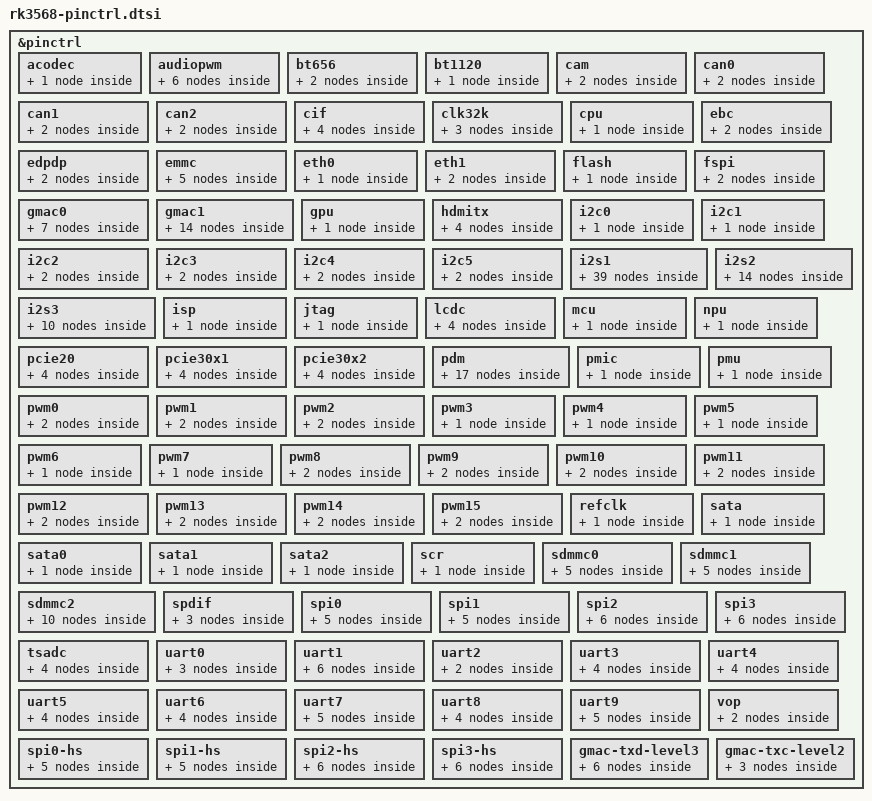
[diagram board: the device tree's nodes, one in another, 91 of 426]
#include <dt-bindings/pinctrl/rockchip.h>
#include "rockchip-pinconf.dtsi"
&pinctrl {
	acodec {
		/omit-if-no-ref/
		acodec_pins: acodec-pins {
			rockchip,pins =
				<1 RK_PB1 5 &pcfg_pull_none>,
				<1 RK_PA1 5 &pcfg_pull_none>,
				<1 RK_PA0 5 &pcfg_pull_none>,
				<1 RK_PA7 5 &pcfg_pull_none>,
				<1 RK_PB0 5 &pcfg_pull_none>,
				<1 RK_PA3 5 &pcfg_pull_none>,
				<1 RK_PA5 5 &pcfg_pull_none>;
		};
	};
	audiopwm {
		/omit-if-no-ref/
		audiopwm_lout: audiopwm-lout {
			rockchip,pins =
				<1 RK_PA0 4 &pcfg_pull_none>;
		};
		/omit-if-no-ref/
		audiopwm_loutn: audiopwm-loutn {
			rockchip,pins =
				<1 RK_PA1 6 &pcfg_pull_none>;
		};
		/omit-if-no-ref/
		audiopwm_loutp: audiopwm-loutp {
			rockchip,pins =
				<1 RK_PA0 6 &pcfg_pull_none>;
		};
		/omit-if-no-ref/
		audiopwm_rout: audiopwm-rout {
			rockchip,pins =
				<1 RK_PA1 4 &pcfg_pull_none>;
		};
		/omit-if-no-ref/
		audiopwm_routn: audiopwm-routn {
			rockchip,pins =
				<1 RK_PA7 4 &pcfg_pull_none>;
		};
		/omit-if-no-ref/
		audiopwm_routp: audiopwm-routp {
			rockchip,pins =
				<1 RK_PA6 4 &pcfg_pull_none>;
		};
	};
	bt656 {
		/omit-if-no-ref/
		bt656m0_pins: bt656m0-pins {
			rockchip,pins =
				<3 RK_PA0 2 &pcfg_pull_none>,
				<2 RK_PD0 2 &pcfg_pull_none>,
				<2 RK_PD1 2 &pcfg_pull_none>,
				<2 RK_PD2 2 &pcfg_pull_none>,
				<2 RK_PD3 2 &pcfg_pull_none>,
				<2 RK_PD4 2 &pcfg_pull_none>,
				<2 RK_PD5 2 &pcfg_pull_none>,
				<2 RK_PD6 2 &pcfg_pull_none>,
				<2 RK_PD7 2 &pcfg_pull_none>;
		};
		/omit-if-no-ref/
		bt656m1_pins: bt656m1-pins {
			rockchip,pins =
				<4 RK_PB4 5 &pcfg_pull_none>,
				<3 RK_PC6 5 &pcfg_pull_none>,
				<3 RK_PC7 5 &pcfg_pull_none>,
				<3 RK_PD0 5 &pcfg_pull_none>,
				<3 RK_PD1 5 &pcfg_pull_none>,
				<3 RK_PD2 5 &pcfg_pull_none>,
				<3 RK_PD3 5 &pcfg_pull_none>,
				<3 RK_PD4 5 &pcfg_pull_none>,
				<3 RK_PD5 5 &pcfg_pull_none>;
		};
	};
	bt1120 {
		/omit-if-no-ref/
		bt1120_pins: bt1120-pins {
			rockchip,pins =
				<3 RK_PA6 2 &pcfg_pull_none>,
				<3 RK_PA1 2 &pcfg_pull_none>,
				<3 RK_PA2 2 &pcfg_pull_none>,
				<3 RK_PA3 2 &pcfg_pull_none>,
				<3 RK_PA4 2 &pcfg_pull_none>,
				<3 RK_PA5 2 &pcfg_pull_none>,
				<3 RK_PA7 2 &pcfg_pull_none>,
				<3 RK_PB0 2 &pcfg_pull_none>,
				<3 RK_PB1 2 &pcfg_pull_none>,
				<3 RK_PB2 2 &pcfg_pull_none>,
				<3 RK_PB3 2 &pcfg_pull_none>,
				<3 RK_PB4 2 &pcfg_pull_none>,
				<3 RK_PB5 2 &pcfg_pull_none>,
				<3 RK_PB6 2 &pcfg_pull_none>,
				<3 RK_PC1 2 &pcfg_pull_none>,
				<3 RK_PC2 2 &pcfg_pull_none>,
				<3 RK_PC3 2 &pcfg_pull_none>;
		};
	};
	cam {
		/omit-if-no-ref/
		cam_clkout0: cam-clkout0 {
			rockchip,pins =
				<4 RK_PA7 1 &pcfg_pull_none>;
		};
		/omit-if-no-ref/
		cam_clkout1: cam-clkout1 {
			rockchip,pins =
				<4 RK_PB0 1 &pcfg_pull_none>;
		};
	};
	can0 {
		/omit-if-no-ref/
		can0m0_pins: can0m0-pins {
			rockchip,pins =
				<0 RK_PB4 2 &pcfg_pull_none>,
				<0 RK_PB3 2 &pcfg_pull_none>;
		};
		/omit-if-no-ref/
		can0m1_pins: can0m1-pins {
			rockchip,pins =
				<2 RK_PA2 4 &pcfg_pull_none>,
				<2 RK_PA1 4 &pcfg_pull_none>;
		};
	};
	can1 {
		/omit-if-no-ref/
		can1m0_pins: can1m0-pins {
			rockchip,pins =
				<1 RK_PA0 3 &pcfg_pull_none>,
				<1 RK_PA1 3 &pcfg_pull_none>;
		};
		/omit-if-no-ref/
		can1m1_pins: can1m1-pins {
			rockchip,pins =
				<4 RK_PC2 3 &pcfg_pull_none>,
				<4 RK_PC3 3 &pcfg_pull_none>;
		};
	};
	can2 {
		/omit-if-no-ref/
		can2m0_pins: can2m0-pins {
			rockchip,pins =
				<4 RK_PB4 3 &pcfg_pull_none>,
				<4 RK_PB5 3 &pcfg_pull_none>;
		};
		/omit-if-no-ref/
		can2m1_pins: can2m1-pins {
			rockchip,pins =
				<2 RK_PB1 4 &pcfg_pull_none>,
				<2 RK_PB2 4 &pcfg_pull_none>;
		};
	};
	cif {
		/omit-if-no-ref/
		cif_clk: cif-clk {
			rockchip,pins =
				<4 RK_PC0 1 &pcfg_pull_none>;
		};
		/omit-if-no-ref/
		cif_dvp_clk: cif-dvp-clk {
			rockchip,pins =
				<4 RK_PC1 1 &pcfg_pull_none>,
				<4 RK_PB6 1 &pcfg_pull_none>,
				<4 RK_PB7 1 &pcfg_pull_none>;
		};
		/omit-if-no-ref/
		cif_dvp_bus16: cif-dvp-bus16 {
			rockchip,pins =
				<3 RK_PD6 1 &pcfg_pull_none>,
				<3 RK_PD7 1 &pcfg_pull_none>,
				<4 RK_PA0 1 &pcfg_pull_none>,
				<4 RK_PA1 1 &pcfg_pull_none>,
				<4 RK_PA2 1 &pcfg_pull_none>,
				<4 RK_PA3 1 &pcfg_pull_none>,
				<4 RK_PA4 1 &pcfg_pull_none>,
				<4 RK_PA5 1 &pcfg_pull_none>;
		};
		/omit-if-no-ref/
		cif_dvp_bus8: cif-dvp-bus8 {
			rockchip,pins =
				<3 RK_PC6 1 &pcfg_pull_none>,
				<3 RK_PC7 1 &pcfg_pull_none>,
				<3 RK_PD0 1 &pcfg_pull_none>,
				<3 RK_PD1 1 &pcfg_pull_none>,
				<3 RK_PD2 1 &pcfg_pull_none>,
				<3 RK_PD3 1 &pcfg_pull_none>,
				<3 RK_PD4 1 &pcfg_pull_none>,
				<3 RK_PD5 1 &pcfg_pull_none>;
		};
	};
	clk32k {
		/omit-if-no-ref/
		clk32k_in: clk32k-in {
			rockchip,pins =
				<0 RK_PB0 1 &pcfg_pull_none>;
		};
		/omit-if-no-ref/
		clk32k_out0: clk32k-out0 {
			rockchip,pins =
				<0 RK_PB0 2 &pcfg_pull_none>;
		};
		/omit-if-no-ref/
		clk32k_out1: clk32k-out1 {
			rockchip,pins =
				<2 RK_PC6 1 &pcfg_pull_none>;
		};
	};
	cpu {
		/omit-if-no-ref/
		cpu_pins: cpu-pins {
			rockchip,pins =
				<0 RK_PB7 2 &pcfg_pull_none>;
		};
	};
	ebc {
		/omit-if-no-ref/
		ebc_extern: ebc-extern {
			rockchip,pins =
				<4 RK_PA7 2 &pcfg_pull_none>,
				<4 RK_PB0 2 &pcfg_pull_none>,
				<4 RK_PB1 2 &pcfg_pull_none>,
				<4 RK_PB5 2 &pcfg_pull_none>,
				<4 RK_PB2 2 &pcfg_pull_none>;
		};
		/omit-if-no-ref/
		ebc_pins: ebc-pins {
			rockchip,pins =
				<4 RK_PC0 2 &pcfg_pull_none>,
				<4 RK_PB3 2 &pcfg_pull_none>,
				<4 RK_PB4 2 &pcfg_pull_none>,
				<4 RK_PA6 2 &pcfg_pull_none>,
				<4 RK_PC1 2 &pcfg_pull_none>,
				<3 RK_PC6 2 &pcfg_pull_none>,
				<3 RK_PC7 2 &pcfg_pull_none>,
				<3 RK_PD0 2 &pcfg_pull_none>,
				<3 RK_PD1 2 &pcfg_pull_none>,
				<3 RK_PD2 2 &pcfg_pull_none>,
				<3 RK_PD3 2 &pcfg_pull_none>,
				<3 RK_PD4 2 &pcfg_pull_none>,
				<3 RK_PD5 2 &pcfg_pull_none>,
				<3 RK_PD6 2 &pcfg_pull_none>,
				<3 RK_PD7 2 &pcfg_pull_none>,
				<4 RK_PA0 2 &pcfg_pull_none>,
				<4 RK_PA1 2 &pcfg_pull_none>,
				<4 RK_PA2 2 &pcfg_pull_none>,
				<4 RK_PA3 2 &pcfg_pull_none>,
				<4 RK_PA4 2 &pcfg_pull_none>,
				<4 RK_PA5 2 &pcfg_pull_none>,
				<4 RK_PB6 2 &pcfg_pull_none>,
				<4 RK_PB7 2 &pcfg_pull_none>;
		};
	};
	edpdp {
		/omit-if-no-ref/
		edpdpm0_pins: edpdpm0-pins {
			rockchip,pins =
				<4 RK_PC4 1 &pcfg_pull_none>;
		};
		/omit-if-no-ref/
		edpdpm1_pins: edpdpm1-pins {
			rockchip,pins =
				<0 RK_PC2 2 &pcfg_pull_none>;
		};
	};
	emmc {
		/omit-if-no-ref/
		emmc_rstnout: emmc-rstnout {
			rockchip,pins =
				<1 RK_PC7 1 &pcfg_pull_none>;
		};
		/omit-if-no-ref/
		emmc_bus8: emmc-bus8 {
			rockchip,pins =
				<1 RK_PB4 1 &pcfg_pull_up_drv_level_2>,
				<1 RK_PB5 1 &pcfg_pull_up_drv_level_2>,
				<1 RK_PB6 1 &pcfg_pull_up_drv_level_2>,
				<1 RK_PB7 1 &pcfg_pull_up_drv_level_2>,
				<1 RK_PC0 1 &pcfg_pull_up_drv_level_2>,
				<1 RK_PC1 1 &pcfg_pull_up_drv_level_2>,
				<1 RK_PC2 1 &pcfg_pull_up_drv_level_2>,
				<1 RK_PC3 1 &pcfg_pull_up_drv_level_2>;
		};
		/omit-if-no-ref/
		emmc_clk: emmc-clk {
			rockchip,pins =
				<1 RK_PC5 1 &pcfg_pull_up_drv_level_2>;
		};
		/omit-if-no-ref/
		emmc_cmd: emmc-cmd {
			rockchip,pins =
				<1 RK_PC4 1 &pcfg_pull_up_drv_level_2>;
		};
		/omit-if-no-ref/
		emmc_datastrobe: emmc-datastrobe {
			rockchip,pins =
				<1 RK_PC6 1 &pcfg_pull_none>;
		};
	};
	eth0 {
		/omit-if-no-ref/
		eth0_pins: eth0-pins {
			rockchip,pins =
				<2 RK_PC1 2 &pcfg_pull_none>;
		};
	};
	eth1 {
		/omit-if-no-ref/
		eth1m0_pins: eth1m0-pins {
			rockchip,pins =
				<3 RK_PB0 3 &pcfg_pull_none>;
		};
		/omit-if-no-ref/
		eth1m1_pins: eth1m1-pins {
			rockchip,pins =
				<4 RK_PB3 3 &pcfg_pull_none>;
		};
	};
	flash {
		/omit-if-no-ref/
		flash_pins: flash-pins {
			rockchip,pins =
				<1 RK_PD0 2 &pcfg_pull_none>,
				<1 RK_PC6 3 &pcfg_pull_none>,
				<1 RK_PD3 2 &pcfg_pull_none>,
				<1 RK_PD4 2 &pcfg_pull_none>,
				<1 RK_PB4 2 &pcfg_pull_none>,
				<1 RK_PB5 2 &pcfg_pull_none>,
				<1 RK_PB6 2 &pcfg_pull_none>,
				<1 RK_PB7 2 &pcfg_pull_none>,
				<1 RK_PC0 2 &pcfg_pull_none>,
				<1 RK_PC1 2 &pcfg_pull_none>,
				<1 RK_PC2 2 &pcfg_pull_none>,
				<1 RK_PC3 2 &pcfg_pull_none>,
				<1 RK_PC5 2 &pcfg_pull_none>,
				<1 RK_PD2 2 &pcfg_pull_none>,
				<1 RK_PD1 2 &pcfg_pull_none>,
				<0 RK_PA7 1 &pcfg_pull_none>,
				<1 RK_PC7 3 &pcfg_pull_none>,
				<1 RK_PC4 2 &pcfg_pull_none>;
		};
	};
	fspi {
		/omit-if-no-ref/
		fspi_pins: fspi-pins {
			rockchip,pins =
				<1 RK_PD0 1 &pcfg_pull_none>,
				<1 RK_PD3 1 &pcfg_pull_none>,
				<1 RK_PD1 1 &pcfg_pull_none>,
				<1 RK_PD2 1 &pcfg_pull_none>,
				<1 RK_PC7 2 &pcfg_pull_none>,
				<1 RK_PD4 1 &pcfg_pull_none>;
		};
		/omit-if-no-ref/
		fspi_cs1: fspi-cs1 {
			rockchip,pins =
				<1 RK_PC6 2 &pcfg_pull_up>;
		};
	};
	gmac0 {
		/omit-if-no-ref/
		gmac0_miim: gmac0-miim {
			rockchip,pins =
				<2 RK_PC3 2 &pcfg_pull_none>,
				<2 RK_PC4 2 &pcfg_pull_none>;
		};
		/omit-if-no-ref/
		gmac0_clkinout: gmac0-clkinout {
			rockchip,pins =
				<2 RK_PC2 2 &pcfg_pull_none>;
		};
		/omit-if-no-ref/
		gmac0_rx_er: gmac0-rx-er {
			rockchip,pins =
				<2 RK_PC5 2 &pcfg_pull_none>;
		};
		/omit-if-no-ref/
		gmac0_rx_bus2: gmac0-rx-bus2 {
			rockchip,pins =
				<2 RK_PB6 1 &pcfg_pull_none>,
				<2 RK_PB7 2 &pcfg_pull_none>,
				<2 RK_PC0 2 &pcfg_pull_none>;
		};
		/omit-if-no-ref/
		gmac0_tx_bus2: gmac0-tx-bus2 {
			rockchip,pins =
				<2 RK_PB3 1 &pcfg_pull_none_drv_level_2>,
				<2 RK_PB4 1 &pcfg_pull_none_drv_level_2>,
				<2 RK_PB5 1 &pcfg_pull_none>;
		};
		/omit-if-no-ref/
		gmac0_rgmii_clk: gmac0-rgmii-clk {
			rockchip,pins =
				<2 RK_PA5 2 &pcfg_pull_none>,
				<2 RK_PB0 2 &pcfg_pull_none_drv_level_1>;
		};
		/omit-if-no-ref/
		gmac0_rgmii_bus: gmac0-rgmii-bus {
			rockchip,pins =
				<2 RK_PA3 2 &pcfg_pull_none>,
				<2 RK_PA4 2 &pcfg_pull_none>,
				<2 RK_PA6 2 &pcfg_pull_none_drv_level_2>,
				<2 RK_PA7 2 &pcfg_pull_none_drv_level_2>;
		};
	};
	gmac1 {
		/omit-if-no-ref/
		gmac1m0_miim: gmac1m0-miim {
			rockchip,pins =
				<3 RK_PC4 3 &pcfg_pull_none>,
				<3 RK_PC5 3 &pcfg_pull_none>;
		};
		/omit-if-no-ref/
		gmac1m0_clkinout: gmac1m0-clkinout {
			rockchip,pins =
				<3 RK_PC0 3 &pcfg_pull_none>;
		};
		/omit-if-no-ref/
		gmac1m0_rx_er: gmac1m0-rx-er {
			rockchip,pins =
				<3 RK_PB4 3 &pcfg_pull_none>;
		};
		/omit-if-no-ref/
		gmac1m0_rx_bus2: gmac1m0-rx-bus2 {
			rockchip,pins =
				<3 RK_PB1 3 &pcfg_pull_none>,
				<3 RK_PB2 3 &pcfg_pull_none>,
				<3 RK_PB3 3 &pcfg_pull_none>;
		};
		/omit-if-no-ref/
		gmac1m0_tx_bus2: gmac1m0-tx-bus2 {
			rockchip,pins =
				<3 RK_PB5 3 &pcfg_pull_none_drv_level_2>,
				<3 RK_PB6 3 &pcfg_pull_none_drv_level_2>,
				<3 RK_PB7 3 &pcfg_pull_none>;
		};
		/omit-if-no-ref/
		gmac1m0_rgmii_clk: gmac1m0-rgmii-clk {
			rockchip,pins =
				<3 RK_PA7 3 &pcfg_pull_none>,
				<3 RK_PA6 3 &pcfg_pull_none_drv_level_1>;
		};
		/omit-if-no-ref/
		gmac1m0_rgmii_bus: gmac1m0-rgmii-bus {
			rockchip,pins =
				<3 RK_PA4 3 &pcfg_pull_none>,
				<3 RK_PA5 3 &pcfg_pull_none>,
				<3 RK_PA2 3 &pcfg_pull_none_drv_level_2>,
				<3 RK_PA3 3 &pcfg_pull_none_drv_level_2>;
		};
		/omit-if-no-ref/
		gmac1m1_miim: gmac1m1-miim {
			rockchip,pins =
				<4 RK_PB6 3 &pcfg_pull_none>,
				<4 RK_PB7 3 &pcfg_pull_none>;
		};
		/omit-if-no-ref/
		gmac1m1_clkinout: gmac1m1-clkinout {
			rockchip,pins =
				<4 RK_PC1 3 &pcfg_pull_none>;
		};
		/omit-if-no-ref/
		gmac1m1_rx_er: gmac1m1-rx-er {
			rockchip,pins =
				<4 RK_PB2 3 &pcfg_pull_none>;
		};
		/omit-if-no-ref/
		gmac1m1_rx_bus2: gmac1m1-rx-bus2 {
			rockchip,pins =
				<4 RK_PA7 3 &pcfg_pull_none>,
				<4 RK_PB0 3 &pcfg_pull_none>,
				<4 RK_PB1 3 &pcfg_pull_none>;
		};
		/omit-if-no-ref/
		gmac1m1_tx_bus2: gmac1m1-tx-bus2 {
			rockchip,pins =
				<4 RK_PA4 3 &pcfg_pull_none_drv_level_2>,
				<4 RK_PA5 3 &pcfg_pull_none_drv_level_2>,
				<4 RK_PA6 3 &pcfg_pull_none>;
		};
		/omit-if-no-ref/
		gmac1m1_rgmii_clk: gmac1m1-rgmii-clk {
			rockchip,pins =
				<4 RK_PA3 3 &pcfg_pull_none>,
				<4 RK_PA0 3 &pcfg_pull_none_drv_level_1>;
		};
		/omit-if-no-ref/
		gmac1m1_rgmii_bus: gmac1m1-rgmii-bus {
			rockchip,pins =
				<4 RK_PA1 3 &pcfg_pull_none>,
				<4 RK_PA2 3 &pcfg_pull_none>,
				<3 RK_PD6 3 &pcfg_pull_none_drv_level_2>,
				<3 RK_PD7 3 &pcfg_pull_none_drv_level_2>;
		};
	};
	gpu {
		/omit-if-no-ref/
		gpu_pins: gpu-pins {
			rockchip,pins =
				<0 RK_PC0 2 &pcfg_pull_none>,
				<0 RK_PA6 4 &pcfg_pull_none>;
		};
	};
	hdmitx {
		/omit-if-no-ref/
		hdmitxm0_cec: hdmitxm0-cec {
			rockchip,pins =
				<4 RK_PD1 1 &pcfg_pull_none>;
		};
		/omit-if-no-ref/
		hdmitxm1_cec: hdmitxm1-cec {
			rockchip,pins =
				<0 RK_PC7 1 &pcfg_pull_none>;
		};
		/omit-if-no-ref/
		hdmitx_scl: hdmitx-scl {
			rockchip,pins =
				<4 RK_PC7 1 &pcfg_pull_none>;
		};
		/omit-if-no-ref/
		hdmitx_sda: hdmitx-sda {
			rockchip,pins =
				<4 RK_PD0 1 &pcfg_pull_none>;
		};
	};
	i2c0 {
		/omit-if-no-ref/
		i2c0_xfer: i2c0-xfer {
			rockchip,pins =
				<0 RK_PB1 1 &pcfg_pull_none_smt>,
				<0 RK_PB2 1 &pcfg_pull_none_smt>;
		};
	};
	i2c1 {
		/omit-if-no-ref/
		i2c1_xfer: i2c1-xfer {
			rockchip,pins =
				<0 RK_PB3 1 &pcfg_pull_none_smt>,
				<0 RK_PB4 1 &pcfg_pull_none_smt>;
		};
	};
	i2c2 {
		/omit-if-no-ref/
		i2c2m0_xfer: i2c2m0-xfer {
			rockchip,pins =
				<0 RK_PB5 1 &pcfg_pull_none_smt>,
				<0 RK_PB6 1 &pcfg_pull_none_smt>;
		};
		/omit-if-no-ref/
		i2c2m1_xfer: i2c2m1-xfer {
			rockchip,pins =
				<4 RK_PB5 1 &pcfg_pull_none_smt>,
				<4 RK_PB4 1 &pcfg_pull_none_smt>;
		};
	};
	i2c3 {
		/omit-if-no-ref/
		i2c3m0_xfer: i2c3m0-xfer {
			rockchip,pins =
				<1 RK_PA1 1 &pcfg_pull_none_smt>,
				<1 RK_PA0 1 &pcfg_pull_none_smt>;
		};
		/omit-if-no-ref/
		i2c3m1_xfer: i2c3m1-xfer {
			rockchip,pins =
				<3 RK_PB5 4 &pcfg_pull_none_smt>,
				<3 RK_PB6 4 &pcfg_pull_none_smt>;
		};
	};
	i2c4 {
		/omit-if-no-ref/
		i2c4m0_xfer: i2c4m0-xfer {
			rockchip,pins =
				<4 RK_PB3 1 &pcfg_pull_none_smt>,
				<4 RK_PB2 1 &pcfg_pull_none_smt>;
		};
		/omit-if-no-ref/
		i2c4m1_xfer: i2c4m1-xfer {
			rockchip,pins =
				<2 RK_PB2 2 &pcfg_pull_none_smt>,
				<2 RK_PB1 2 &pcfg_pull_none_smt>;
		};
	};
	i2c5 {
		/omit-if-no-ref/
		i2c5m0_xfer: i2c5m0-xfer {
			rockchip,pins =
				<3 RK_PB3 4 &pcfg_pull_none_smt>,
				<3 RK_PB4 4 &pcfg_pull_none_smt>;
		};
		/omit-if-no-ref/
		i2c5m1_xfer: i2c5m1-xfer {
			rockchip,pins =
				<4 RK_PC7 2 &pcfg_pull_none_smt>,
				<4 RK_PD0 2 &pcfg_pull_none_smt>;
		};
	};
	i2s1 {
		/omit-if-no-ref/
		i2s1m0_lrckrx: i2s1m0-lrckrx {
			rockchip,pins =
				<1 RK_PA6 1 &pcfg_pull_none>;
		};
		/omit-if-no-ref/
		i2s1m0_lrcktx: i2s1m0-lrcktx {
			rockchip,pins =
				<1 RK_PA5 1 &pcfg_pull_none>;
		};
		/omit-if-no-ref/
		i2s1m0_mclk: i2s1m0-mclk {
			rockchip,pins =
				<1 RK_PA2 1 &pcfg_pull_none>;
		};
		/omit-if-no-ref/
		i2s1m0_sclkrx: i2s1m0-sclkrx {
			rockchip,pins =
				<1 RK_PA4 1 &pcfg_pull_none>;
		};
		/omit-if-no-ref/
		i2s1m0_sclktx: i2s1m0-sclktx {
			rockchip,pins =
				<1 RK_PA3 1 &pcfg_pull_none>;
		};
		/omit-if-no-ref/
		i2s1m0_sdi0: i2s1m0-sdi0 {
			rockchip,pins =
				<1 RK_PB3 1 &pcfg_pull_none>;
		};
		/omit-if-no-ref/
		i2s1m0_sdi1: i2s1m0-sdi1 {
			rockchip,pins =
				<1 RK_PB2 2 &pcfg_pull_none>;
		};
		/omit-if-no-ref/
		i2s1m0_sdi2: i2s1m0-sdi2 {
			rockchip,pins =
				<1 RK_PB1 2 &pcfg_pull_none>;
		};
		/omit-if-no-ref/
		i2s1m0_sdi3: i2s1m0-sdi3 {
			rockchip,pins =
				<1 RK_PB0 2 &pcfg_pull_none>;
		};
		/omit-if-no-ref/
		i2s1m0_sdo0: i2s1m0-sdo0 {
			rockchip,pins =
				<1 RK_PA7 1 &pcfg_pull_none>;
		};
		/omit-if-no-ref/
		i2s1m0_sdo1: i2s1m0-sdo1 {
			rockchip,pins =
				<1 RK_PB0 1 &pcfg_pull_none>;
		};
		/omit-if-no-ref/
		i2s1m0_sdo2: i2s1m0-sdo2 {
			rockchip,pins =
				<1 RK_PB1 1 &pcfg_pull_none>;
		};
		/omit-if-no-ref/
		i2s1m0_sdo3: i2s1m0-sdo3 {
			rockchip,pins =
				<1 RK_PB2 1 &pcfg_pull_none>;
		};
		/omit-if-no-ref/
		i2s1m1_lrckrx: i2s1m1-lrckrx {
			rockchip,pins =
				<4 RK_PA7 5 &pcfg_pull_none>;
		};
		/omit-if-no-ref/
		i2s1m1_lrcktx: i2s1m1-lrcktx {
			rockchip,pins =
				<3 RK_PD0 4 &pcfg_pull_none>;
		};
		/omit-if-no-ref/
		i2s1m1_mclk: i2s1m1-mclk {
			rockchip,pins =
				<3 RK_PC6 4 &pcfg_pull_none>;
		};
		/omit-if-no-ref/
		i2s1m1_sclkrx: i2s1m1-sclkrx {
			rockchip,pins =
				<4 RK_PA6 5 &pcfg_pull_none>;
		};
		/omit-if-no-ref/
		i2s1m1_sclktx: i2s1m1-sclktx {
			rockchip,pins =
				<3 RK_PC7 4 &pcfg_pull_none>;
		};
		/omit-if-no-ref/
		i2s1m1_sdi0: i2s1m1-sdi0 {
			rockchip,pins =
				<3 RK_PD2 4 &pcfg_pull_none>;
		};
		/omit-if-no-ref/
		i2s1m1_sdi1: i2s1m1-sdi1 {
			rockchip,pins =
				<3 RK_PD3 4 &pcfg_pull_none>;
		};
		/omit-if-no-ref/
		i2s1m1_sdi2: i2s1m1-sdi2 {
			rockchip,pins =
				<3 RK_PD4 4 &pcfg_pull_none>;
		};
		/omit-if-no-ref/
		i2s1m1_sdi3: i2s1m1-sdi3 {
			rockchip,pins =
				<3 RK_PD5 4 &pcfg_pull_none>;
		};
		/omit-if-no-ref/
		i2s1m1_sdo0: i2s1m1-sdo0 {
			rockchip,pins =
				<3 RK_PD1 4 &pcfg_pull_none>;
		};
		/omit-if-no-ref/
		i2s1m1_sdo1: i2s1m1-sdo1 {
			rockchip,pins =
				<4 RK_PB0 5 &pcfg_pull_none>;
		};
		/omit-if-no-ref/
		i2s1m1_sdo2: i2s1m1-sdo2 {
			rockchip,pins =
				<4 RK_PB1 4 &pcfg_pull_none>;
		};
		/omit-if-no-ref/
		i2s1m1_sdo3: i2s1m1-sdo3 {
			rockchip,pins =
				<4 RK_PB5 4 &pcfg_pull_none>;
		};
		/omit-if-no-ref/
		i2s1m2_lrckrx: i2s1m2-lrckrx {
			rockchip,pins =
				<3 RK_PC5 5 &pcfg_pull_none>;
		};
		/omit-if-no-ref/
		i2s1m2_lrcktx: i2s1m2-lrcktx {
			rockchip,pins =
				<2 RK_PD2 5 &pcfg_pull_none>;
		};
		/omit-if-no-ref/
		i2s1m2_mclk: i2s1m2-mclk {
			rockchip,pins =
				<2 RK_PD0 5 &pcfg_pull_none>;
		};
		/omit-if-no-ref/
		i2s1m2_sclkrx: i2s1m2-sclkrx {
			rockchip,pins =
				<3 RK_PC3 5 &pcfg_pull_none>;
		};
		/omit-if-no-ref/
		i2s1m2_sclktx: i2s1m2-sclktx {
			rockchip,pins =
				<2 RK_PD1 5 &pcfg_pull_none>;
		};
		/omit-if-no-ref/
		i2s1m2_sdi0: i2s1m2-sdi0 {
			rockchip,pins =
				<2 RK_PD3 5 &pcfg_pull_none>;
		};
		/omit-if-no-ref/
		i2s1m2_sdi1: i2s1m2-sdi1 {
			rockchip,pins =
				<2 RK_PD4 5 &pcfg_pull_none>;
		};
		/omit-if-no-ref/
		i2s1m2_sdi2: i2s1m2-sdi2 {
			rockchip,pins =
				<2 RK_PD5 5 &pcfg_pull_none>;
		};
		/omit-if-no-ref/
		i2s1m2_sdi3: i2s1m2-sdi3 {
			rockchip,pins =
				<2 RK_PD6 5 &pcfg_pull_none>;
		};
		/omit-if-no-ref/
		i2s1m2_sdo0: i2s1m2-sdo0 {
			rockchip,pins =
				<2 RK_PD7 5 &pcfg_pull_none>;
		};
		/omit-if-no-ref/
		i2s1m2_sdo1: i2s1m2-sdo1 {
			rockchip,pins =
				<3 RK_PA0 5 &pcfg_pull_none>;
		};
		/omit-if-no-ref/
		i2s1m2_sdo2: i2s1m2-sdo2 {
			rockchip,pins =
				<3 RK_PC1 5 &pcfg_pull_none>;
		};
		/omit-if-no-ref/
		i2s1m2_sdo3: i2s1m2-sdo3 {
			rockchip,pins =
				<3 RK_PC2 5 &pcfg_pull_none>;
		};
	};
	i2s2 {
		/omit-if-no-ref/
		i2s2m0_lrckrx: i2s2m0-lrckrx {
			rockchip,pins =
				<2 RK_PC0 1 &pcfg_pull_none>;
		};
		/omit-if-no-ref/
		i2s2m0_lrcktx: i2s2m0-lrcktx {
			rockchip,pins =
				<2 RK_PC3 1 &pcfg_pull_none>;
		};
		/omit-if-no-ref/
		i2s2m0_mclk: i2s2m0-mclk {
			rockchip,pins =
				<2 RK_PC1 1 &pcfg_pull_none>;
		};
		/omit-if-no-ref/
		i2s2m0_sclkrx: i2s2m0-sclkrx {
			rockchip,pins =
				<2 RK_PB7 1 &pcfg_pull_none>;
		};
		/omit-if-no-ref/
		i2s2m0_sclktx: i2s2m0-sclktx {
			rockchip,pins =
				<2 RK_PC2 1 &pcfg_pull_none>;
		};
		/omit-if-no-ref/
		i2s2m0_sdi: i2s2m0-sdi {
			rockchip,pins =
				<2 RK_PC5 1 &pcfg_pull_none>;
		};
		/omit-if-no-ref/
		i2s2m0_sdo: i2s2m0-sdo {
			rockchip,pins =
				<2 RK_PC4 1 &pcfg_pull_none>;
		};
		/omit-if-no-ref/
		i2s2m1_lrckrx: i2s2m1-lrckrx {
			rockchip,pins =
				<4 RK_PA5 5 &pcfg_pull_none>;
		};
		/omit-if-no-ref/
		i2s2m1_lrcktx: i2s2m1-lrcktx {
			rockchip,pins =
				<4 RK_PA4 5 &pcfg_pull_none>;
		};
		/omit-if-no-ref/
		i2s2m1_mclk: i2s2m1-mclk {
			rockchip,pins =
				<4 RK_PB6 5 &pcfg_pull_none>;
		};
		/omit-if-no-ref/
		i2s2m1_sclkrx: i2s2m1-sclkrx {
			rockchip,pins =
				<4 RK_PC1 5 &pcfg_pull_none>;
		};
		/omit-if-no-ref/
		i2s2m1_sclktx: i2s2m1-sclktx {
			rockchip,pins =
				<4 RK_PB7 4 &pcfg_pull_none>;
		};
		/omit-if-no-ref/
		i2s2m1_sdi: i2s2m1-sdi {
			rockchip,pins =
				<4 RK_PB2 5 &pcfg_pull_none>;
		};
		/omit-if-no-ref/
		i2s2m1_sdo: i2s2m1-sdo {
			rockchip,pins =
				<4 RK_PB3 5 &pcfg_pull_none>;
		};
	};
	i2s3 {
		/omit-if-no-ref/
		i2s3m0_lrck: i2s3m0-lrck {
			rockchip,pins =
				<3 RK_PA4 4 &pcfg_pull_none>;
		};
		/omit-if-no-ref/
		i2s3m0_mclk: i2s3m0-mclk {
			rockchip,pins =
				<3 RK_PA2 4 &pcfg_pull_none>;
		};
		/omit-if-no-ref/
		i2s3m0_sclk: i2s3m0-sclk {
			rockchip,pins =
				<3 RK_PA3 4 &pcfg_pull_none>;
		};
		/omit-if-no-ref/
		i2s3m0_sdi: i2s3m0-sdi {
			rockchip,pins =
				<3 RK_PA6 4 &pcfg_pull_none>;
		};
		/omit-if-no-ref/
		i2s3m0_sdo: i2s3m0-sdo {
			rockchip,pins =
				<3 RK_PA5 4 &pcfg_pull_none>;
		};
		/omit-if-no-ref/
		i2s3m1_lrck: i2s3m1-lrck {
			rockchip,pins =
				<4 RK_PC4 5 &pcfg_pull_none>;
		};
		/omit-if-no-ref/
		i2s3m1_mclk: i2s3m1-mclk {
			rockchip,pins =
				<4 RK_PC2 5 &pcfg_pull_none>;
		};
		/omit-if-no-ref/
		i2s3m1_sclk: i2s3m1-sclk {
			rockchip,pins =
				<4 RK_PC3 5 &pcfg_pull_none>;
		};
		/omit-if-no-ref/
		i2s3m1_sdi: i2s3m1-sdi {
			rockchip,pins =
				<4 RK_PC6 5 &pcfg_pull_none>;
		};
		/omit-if-no-ref/
		i2s3m1_sdo: i2s3m1-sdo {
			rockchip,pins =
				<4 RK_PC5 5 &pcfg_pull_none>;
		};
	};
	isp {
		/omit-if-no-ref/
		isp_pins: isp-pins {
			rockchip,pins =
				<4 RK_PB4 4 &pcfg_pull_none>,
				<4 RK_PA6 1 &pcfg_pull_none>,
				<4 RK_PB1 1 &pcfg_pull_none>;
		};
	};
	jtag {
		/omit-if-no-ref/
		jtag_pins: jtag-pins {
			rockchip,pins =
				<1 RK_PD7 2 &pcfg_pull_none>,
				<2 RK_PA0 2 &pcfg_pull_none>;
		};
	};
	lcdc {
		/omit-if-no-ref/
		lcdc_ctl: lcdc-ctl {
			rockchip,pins =
				<3 RK_PA0 1 &pcfg_pull_none>,
				<2 RK_PD0 1 &pcfg_pull_none>,
				<2 RK_PD1 1 &pcfg_pull_none>,
				<2 RK_PD2 1 &pcfg_pull_none>,
				<2 RK_PD3 1 &pcfg_pull_none>,
				<2 RK_PD4 1 &pcfg_pull_none>,
				<2 RK_PD5 1 &pcfg_pull_none>,
				<2 RK_PD6 1 &pcfg_pull_none>,
				<2 RK_PD7 1 &pcfg_pull_none>,
				<3 RK_PA1 1 &pcfg_pull_none>,
				<3 RK_PA2 1 &pcfg_pull_none>,
				<3 RK_PA3 1 &pcfg_pull_none>,
				<3 RK_PA4 1 &pcfg_pull_none>,
				<3 RK_PA5 1 &pcfg_pull_none>,
				<3 RK_PA6 1 &pcfg_pull_none>,
				<3 RK_PA7 1 &pcfg_pull_none>,
				<3 RK_PB0 1 &pcfg_pull_none>,
				<3 RK_PB1 1 &pcfg_pull_none>,
				<3 RK_PB2 1 &pcfg_pull_none>,
				<3 RK_PB3 1 &pcfg_pull_none>,
				<3 RK_PB4 1 &pcfg_pull_none>,
				<3 RK_PB5 1 &pcfg_pull_none>,
				<3 RK_PB6 1 &pcfg_pull_none>,
				<3 RK_PB7 1 &pcfg_pull_none>,
				<3 RK_PC0 1 &pcfg_pull_none>,
				<3 RK_PC3 1 &pcfg_pull_none>,
				<3 RK_PC1 1 &pcfg_pull_none>,
				<3 RK_PC2 1 &pcfg_pull_none>;
		};
	};
	mcu {
		/omit-if-no-ref/
		mcu_pins: mcu-pins {
			rockchip,pins =
				<0 RK_PB4 4 &pcfg_pull_none>,
				<0 RK_PC1 4 &pcfg_pull_none>,
				<0 RK_PB3 4 &pcfg_pull_none>,
				<0 RK_PC2 4 &pcfg_pull_none>,
				<0 RK_PC3 4 &pcfg_pull_none>;
		};
	};
	npu {
		/omit-if-no-ref/
		npu_pins: npu-pins {
			rockchip,pins =
				<0 RK_PC1 2 &pcfg_pull_none>;
		};
	};
	pcie20 {
		/omit-if-no-ref/
		pcie20m0_pins: pcie20m0-pins {
			rockchip,pins =
				<0 RK_PA5 3 &pcfg_pull_none>,
				<0 RK_PB6 3 &pcfg_pull_none>,
				<0 RK_PB5 3 &pcfg_pull_none>;
		};
		/omit-if-no-ref/
		pcie20m1_pins: pcie20m1-pins {
			rockchip,pins =
				<2 RK_PD0 4 &pcfg_pull_none>,
				<3 RK_PC1 4 &pcfg_pull_none>,
				<2 RK_PD1 4 &pcfg_pull_none>;
		};
		/omit-if-no-ref/
		pcie20m2_pins: pcie20m2-pins {
			rockchip,pins =
				<1 RK_PB0 4 &pcfg_pull_none>,
				<1 RK_PB2 4 &pcfg_pull_none>,
				<1 RK_PB1 4 &pcfg_pull_none>;
		};
		/omit-if-no-ref/
		pcie20_buttonrstn: pcie20-buttonrstn {
			rockchip,pins =
				<0 RK_PB4 3 &pcfg_pull_none>;
		};
	};
	pcie30x1 {
		/omit-if-no-ref/
		pcie30x1m0_pins: pcie30x1m0-pins {
			rockchip,pins =
				<0 RK_PA4 3 &pcfg_pull_none>,
				<0 RK_PC3 3 &pcfg_pull_none>,
				<0 RK_PC2 3 &pcfg_pull_none>;
		};
		/omit-if-no-ref/
		pcie30x1m1_pins: pcie30x1m1-pins {
			rockchip,pins =
				<2 RK_PD2 4 &pcfg_pull_none>,
				<3 RK_PA1 4 &pcfg_pull_none>,
				<2 RK_PD3 4 &pcfg_pull_none>;
		};
		/omit-if-no-ref/
		pcie30x1m2_pins: pcie30x1m2-pins {
			rockchip,pins =
				<1 RK_PA5 4 &pcfg_pull_none>,
				<1 RK_PA2 4 &pcfg_pull_none>,
				<1 RK_PA3 4 &pcfg_pull_none>;
		};
		/omit-if-no-ref/
		pcie30x1_buttonrstn: pcie30x1-buttonrstn {
			rockchip,pins =
				<0 RK_PB3 3 &pcfg_pull_none>;
		};
	};
	pcie30x2 {
		/omit-if-no-ref/
		pcie30x2m0_pins: pcie30x2m0-pins {
			rockchip,pins =
				<0 RK_PA6 2 &pcfg_pull_none>,
				<0 RK_PC6 3 &pcfg_pull_none>,
				<0 RK_PC5 3 &pcfg_pull_none>;
		};
		/omit-if-no-ref/
		pcie30x2m1_pins: pcie30x2m1-pins {
			rockchip,pins =
				<2 RK_PD4 4 &pcfg_pull_none>,
				<2 RK_PD6 4 &pcfg_pull_none>,
				<2 RK_PD5 4 &pcfg_pull_none>;
		};
		/omit-if-no-ref/
		pcie30x2m2_pins: pcie30x2m2-pins {
			rockchip,pins =
				<4 RK_PC2 4 &pcfg_pull_none>,
				<4 RK_PC4 4 &pcfg_pull_none>,
				<4 RK_PC3 4 &pcfg_pull_none>;
		};
		/omit-if-no-ref/
		pcie30x2_buttonrstn: pcie30x2-buttonrstn {
			rockchip,pins =
				<0 RK_PB0 3 &pcfg_pull_none>;
		};
	};
	pdm {
		/omit-if-no-ref/
		pdmm0_clk: pdmm0-clk {
			rockchip,pins =
				<1 RK_PA6 3 &pcfg_pull_none>;
		};
		/omit-if-no-ref/
		pdmm0_clk1: pdmm0-clk1 {
			rockchip,pins =
				<1 RK_PA4 3 &pcfg_pull_none>;
		};
		/omit-if-no-ref/
		pdmm0_sdi0: pdmm0-sdi0 {
			rockchip,pins =
				<1 RK_PB3 2 &pcfg_pull_none>;
		};
		/omit-if-no-ref/
		pdmm0_sdi1: pdmm0-sdi1 {
			rockchip,pins =
				<1 RK_PB2 3 &pcfg_pull_none>;
		};
		/omit-if-no-ref/
		pdmm0_sdi2: pdmm0-sdi2 {
			rockchip,pins =
				<1 RK_PB1 3 &pcfg_pull_none>;
		};
		/omit-if-no-ref/
		pdmm0_sdi3: pdmm0-sdi3 {
			rockchip,pins =
				<1 RK_PB0 3 &pcfg_pull_none>;
		};
		/omit-if-no-ref/
		pdmm1_clk: pdmm1-clk {
			rockchip,pins =
				<3 RK_PD6 5 &pcfg_pull_none>;
		};
		/omit-if-no-ref/
		pdmm1_clk1: pdmm1-clk1 {
			rockchip,pins =
				<4 RK_PA0 4 &pcfg_pull_none>;
		};
		/omit-if-no-ref/
		pdmm1_sdi0: pdmm1-sdi0 {
			rockchip,pins =
				<3 RK_PD7 5 &pcfg_pull_none>;
		};
		/omit-if-no-ref/
		pdmm1_sdi1: pdmm1-sdi1 {
			rockchip,pins =
				<4 RK_PA1 4 &pcfg_pull_none>;
		};
		/omit-if-no-ref/
		pdmm1_sdi2: pdmm1-sdi2 {
			rockchip,pins =
				<4 RK_PA2 5 &pcfg_pull_none>;
		};
		/omit-if-no-ref/
		pdmm1_sdi3: pdmm1-sdi3 {
			rockchip,pins =
				<4 RK_PA3 5 &pcfg_pull_none>;
		};
		/omit-if-no-ref/
		pdmm2_clk1: pdmm2-clk1 {
			rockchip,pins =
				<3 RK_PC4 5 &pcfg_pull_none>;
		};
		/omit-if-no-ref/
		pdmm2_sdi0: pdmm2-sdi0 {
			rockchip,pins =
				<3 RK_PB3 5 &pcfg_pull_none>;
		};
		/omit-if-no-ref/
		pdmm2_sdi1: pdmm2-sdi1 {
			rockchip,pins =
				<3 RK_PB4 5 &pcfg_pull_none>;
		};
		/omit-if-no-ref/
		pdmm2_sdi2: pdmm2-sdi2 {
			rockchip,pins =
				<3 RK_PB7 5 &pcfg_pull_none>;
		};
		/omit-if-no-ref/
		pdmm2_sdi3: pdmm2-sdi3 {
			rockchip,pins =
				<3 RK_PC0 5 &pcfg_pull_none>;
		};
	};
	pmic {
		/omit-if-no-ref/
		pmic_pins: pmic-pins {
			rockchip,pins =
				<0 RK_PA2 1 &pcfg_pull_none>;
		};
	};
	pmu {
		/omit-if-no-ref/
		pmu_pins: pmu-pins {
			rockchip,pins =
				<0 RK_PA5 4 &pcfg_pull_none>,
				<0 RK_PA6 3 &pcfg_pull_none>,
				<0 RK_PC4 4 &pcfg_pull_none>,
				<0 RK_PC5 4 &pcfg_pull_none>,
				<0 RK_PC6 4 &pcfg_pull_none>,
				<0 RK_PC7 4 &pcfg_pull_none>;
		};
	};
	pwm0 {
		/omit-if-no-ref/
		pwm0m0_pins: pwm0m0-pins {
			rockchip,pins =
				<0 RK_PB7 1 &pcfg_pull_none>;
		};
		/omit-if-no-ref/
		pwm0m1_pins: pwm0m1-pins {
			rockchip,pins =
				<0 RK_PC7 2 &pcfg_pull_none>;
		};
	};
	pwm1 {
		/omit-if-no-ref/
		pwm1m0_pins: pwm1m0-pins {
			rockchip,pins =
				<0 RK_PC0 1 &pcfg_pull_none>;
		};
		/omit-if-no-ref/
		pwm1m1_pins: pwm1m1-pins {
			rockchip,pins =
				<0 RK_PB5 4 &pcfg_pull_none>;
		};
	};
	pwm2 {
		/omit-if-no-ref/
		pwm2m0_pins: pwm2m0-pins {
			rockchip,pins =
				<0 RK_PC1 1 &pcfg_pull_none>;
		};
		/omit-if-no-ref/
		pwm2m1_pins: pwm2m1-pins {
			rockchip,pins =
				<0 RK_PB6 4 &pcfg_pull_none>;
		};
	};
	pwm3 {
		/omit-if-no-ref/
		pwm3_pins: pwm3-pins {
			rockchip,pins =
				<0 RK_PC2 1 &pcfg_pull_none>;
		};
	};
	pwm4 {
		/omit-if-no-ref/
		pwm4_pins: pwm4-pins {
			rockchip,pins =
				<0 RK_PC3 1 &pcfg_pull_none>;
		};
	};
	pwm5 {
		/omit-if-no-ref/
		pwm5_pins: pwm5-pins {
			rockchip,pins =
				<0 RK_PC4 1 &pcfg_pull_none>;
		};
	};
	pwm6 {
		/omit-if-no-ref/
		pwm6_pins: pwm6-pins {
			rockchip,pins =
				<0 RK_PC5 1 &pcfg_pull_none>;
		};
	};
	pwm7 {
		/omit-if-no-ref/
		pwm7_pins: pwm7-pins {
			rockchip,pins =
				<0 RK_PC6 1 &pcfg_pull_none>;
		};
	};
	pwm8 {
		/omit-if-no-ref/
		pwm8m0_pins: pwm8m0-pins {
			rockchip,pins =
				<3 RK_PB1 5 &pcfg_pull_none>;
		};
		/omit-if-no-ref/
		pwm8m1_pins: pwm8m1-pins {
			rockchip,pins =
				<1 RK_PD5 4 &pcfg_pull_none>;
		};
	};
	pwm9 {
		/omit-if-no-ref/
		pwm9m0_pins: pwm9m0-pins {
			rockchip,pins =
				<3 RK_PB2 5 &pcfg_pull_none>;
		};
		/omit-if-no-ref/
		pwm9m1_pins: pwm9m1-pins {
			rockchip,pins =
				<1 RK_PD6 4 &pcfg_pull_none>;
		};
	};
	pwm10 {
		/omit-if-no-ref/
		pwm10m0_pins: pwm10m0-pins {
			rockchip,pins =
				<3 RK_PB5 5 &pcfg_pull_none>;
		};
		/omit-if-no-ref/
		pwm10m1_pins: pwm10m1-pins {
			rockchip,pins =
				<2 RK_PA1 2 &pcfg_pull_none>;
		};
	};
	pwm11 {
		/omit-if-no-ref/
		pwm11m0_pins: pwm11m0-pins {
			rockchip,pins =
				<3 RK_PB6 5 &pcfg_pull_none>;
		};
		/omit-if-no-ref/
		pwm11m1_pins: pwm11m1-pins {
			rockchip,pins =
				<4 RK_PC0 3 &pcfg_pull_none>;
		};
	};
	pwm12 {
		/omit-if-no-ref/
		pwm12m0_pins: pwm12m0-pins {
			rockchip,pins =
				<3 RK_PB7 2 &pcfg_pull_none>;
		};
		/omit-if-no-ref/
		pwm12m1_pins: pwm12m1-pins {
			rockchip,pins =
				<4 RK_PC5 1 &pcfg_pull_none>;
		};
	};
	pwm13 {
		/omit-if-no-ref/
		pwm13m0_pins: pwm13m0-pins {
			rockchip,pins =
				<3 RK_PC0 2 &pcfg_pull_none>;
		};
		/omit-if-no-ref/
		pwm13m1_pins: pwm13m1-pins {
			rockchip,pins =
				<4 RK_PC6 1 &pcfg_pull_none>;
		};
	};
	pwm14 {
		/omit-if-no-ref/
		pwm14m0_pins: pwm14m0-pins {
			rockchip,pins =
				<3 RK_PC4 1 &pcfg_pull_none>;
		};
		/omit-if-no-ref/
		pwm14m1_pins: pwm14m1-pins {
			rockchip,pins =
				<4 RK_PC2 1 &pcfg_pull_none>;
		};
	};
	pwm15 {
		/omit-if-no-ref/
		pwm15m0_pins: pwm15m0-pins {
			rockchip,pins =
				<3 RK_PC5 1 &pcfg_pull_none>;
		};
		/omit-if-no-ref/
		pwm15m1_pins: pwm15m1-pins {
			rockchip,pins =
				<4 RK_PC3 1 &pcfg_pull_none>;
		};
	};
	refclk {
		/omit-if-no-ref/
		refclk_pins: refclk-pins {
			rockchip,pins =
				<0 RK_PA0 1 &pcfg_pull_none>;
		};
	};
	sata {
		/omit-if-no-ref/
		sata_pins: sata-pins {
			rockchip,pins =
				<0 RK_PA4 2 &pcfg_pull_none>,
				<0 RK_PA6 1 &pcfg_pull_none>,
				<0 RK_PA5 2 &pcfg_pull_none>;
		};
	};
	sata0 {
		/omit-if-no-ref/
		sata0_pins: sata0-pins {
			rockchip,pins =
				<4 RK_PC6 3 &pcfg_pull_none>;
		};
	};
	sata1 {
		/omit-if-no-ref/
		sata1_pins: sata1-pins {
			rockchip,pins =
				<4 RK_PC5 3 &pcfg_pull_none>;
		};
	};
	sata2 {
		/omit-if-no-ref/
		sata2_pins: sata2-pins {
			rockchip,pins =
				<4 RK_PC4 3 &pcfg_pull_none>;
		};
	};
	scr {
		/omit-if-no-ref/
		scr_pins: scr-pins {
			rockchip,pins =
				<1 RK_PA2 3 &pcfg_pull_none>,
				<1 RK_PA7 3 &pcfg_pull_up>,
				<1 RK_PA3 3 &pcfg_pull_up>,
				<1 RK_PA5 3 &pcfg_pull_none>;
		};
	};
	sdmmc0 {
		/omit-if-no-ref/
		sdmmc0_bus4: sdmmc0-bus4 {
			rockchip,pins =
				<1 RK_PD5 1 &pcfg_pull_up_drv_level_2>,
				<1 RK_PD6 1 &pcfg_pull_up_drv_level_2>,
				<1 RK_PD7 1 &pcfg_pull_up_drv_level_2>,
				<2 RK_PA0 1 &pcfg_pull_up_drv_level_2>;
		};
		/omit-if-no-ref/
		sdmmc0_clk: sdmmc0-clk {
			rockchip,pins =
				<2 RK_PA2 1 &pcfg_pull_up_drv_level_2>;
		};
		/omit-if-no-ref/
		sdmmc0_cmd: sdmmc0-cmd {
			rockchip,pins =
				<2 RK_PA1 1 &pcfg_pull_up_drv_level_2>;
		};
		/omit-if-no-ref/
		sdmmc0_det: sdmmc0-det {
			rockchip,pins =
				<0 RK_PA4 1 &pcfg_pull_up>;
		};
		/omit-if-no-ref/
		sdmmc0_pwren: sdmmc0-pwren {
			rockchip,pins =
				<0 RK_PA5 1 &pcfg_pull_none>;
		};
	};
	sdmmc1 {
		/omit-if-no-ref/
		sdmmc1_bus4: sdmmc1-bus4 {
			rockchip,pins =
				<2 RK_PA3 1 &pcfg_pull_up_drv_level_2>,
				<2 RK_PA4 1 &pcfg_pull_up_drv_level_2>,
				<2 RK_PA5 1 &pcfg_pull_up_drv_level_2>,
				<2 RK_PA6 1 &pcfg_pull_up_drv_level_2>;
		};
		/omit-if-no-ref/
		sdmmc1_clk: sdmmc1-clk {
			rockchip,pins =
				<2 RK_PB0 1 &pcfg_pull_up_drv_level_2>;
		};
		/omit-if-no-ref/
		sdmmc1_cmd: sdmmc1-cmd {
			rockchip,pins =
				<2 RK_PA7 1 &pcfg_pull_up_drv_level_2>;
		};
		/omit-if-no-ref/
		sdmmc1_det: sdmmc1-det {
			rockchip,pins =
				<2 RK_PB2 1 &pcfg_pull_up>;
		};
		/omit-if-no-ref/
		sdmmc1_pwren: sdmmc1-pwren {
			rockchip,pins =
				<2 RK_PB1 1 &pcfg_pull_none>;
		};
	};
	sdmmc2 {
		/omit-if-no-ref/
		sdmmc2m0_bus4: sdmmc2m0-bus4 {
			rockchip,pins =
				<3 RK_PC6 3 &pcfg_pull_up_drv_level_2>,
				<3 RK_PC7 3 &pcfg_pull_up_drv_level_2>,
				<3 RK_PD0 3 &pcfg_pull_up_drv_level_2>,
				<3 RK_PD1 3 &pcfg_pull_up_drv_level_2>;
		};
		/omit-if-no-ref/
		sdmmc2m0_clk: sdmmc2m0-clk {
			rockchip,pins =
				<3 RK_PD3 3 &pcfg_pull_up_drv_level_2>;
		};
		/omit-if-no-ref/
		sdmmc2m0_cmd: sdmmc2m0-cmd {
			rockchip,pins =
				<3 RK_PD2 3 &pcfg_pull_up_drv_level_2>;
		};
		/omit-if-no-ref/
		sdmmc2m0_det: sdmmc2m0-det {
			rockchip,pins =
				<3 RK_PD4 3 &pcfg_pull_up>;
		};
		/omit-if-no-ref/
		sdmmc2m0_pwren: sdmmc2m0-pwren {
			rockchip,pins =
				<3 RK_PD5 3 &pcfg_pull_none>;
		};
		/omit-if-no-ref/
		sdmmc2m1_bus4: sdmmc2m1-bus4 {
			rockchip,pins =
				<3 RK_PA1 5 &pcfg_pull_up_drv_level_2>,
				<3 RK_PA2 5 &pcfg_pull_up_drv_level_2>,
				<3 RK_PA3 5 &pcfg_pull_up_drv_level_2>,
				<3 RK_PA4 5 &pcfg_pull_up_drv_level_2>;
		};
		/omit-if-no-ref/
		sdmmc2m1_clk: sdmmc2m1-clk {
			rockchip,pins =
				<3 RK_PA6 5 &pcfg_pull_up_drv_level_2>;
		};
		/omit-if-no-ref/
		sdmmc2m1_cmd: sdmmc2m1-cmd {
			rockchip,pins =
				<3 RK_PA5 5 &pcfg_pull_up_drv_level_2>;
		};
		/omit-if-no-ref/
		sdmmc2m1_det: sdmmc2m1-det {
			rockchip,pins =
				<3 RK_PA7 4 &pcfg_pull_up>;
		};
		/omit-if-no-ref/
		sdmmc2m1_pwren: sdmmc2m1-pwren {
			rockchip,pins =
				<3 RK_PB0 4 &pcfg_pull_none>;
		};
	};
	spdif {
		/omit-if-no-ref/
		spdifm0_tx: spdifm0-tx {
			rockchip,pins =
				<1 RK_PA4 4 &pcfg_pull_none>;
		};
		/omit-if-no-ref/
		spdifm1_tx: spdifm1-tx {
			rockchip,pins =
				<3 RK_PC5 2 &pcfg_pull_none>;
		};
		/omit-if-no-ref/
		spdifm2_tx: spdifm2-tx {
			rockchip,pins =
				<4 RK_PC4 2 &pcfg_pull_none>;
		};
	};
	spi0 {
		/omit-if-no-ref/
		spi0m0_pins: spi0m0-pins {
			rockchip,pins =
				<0 RK_PB5 2 &pcfg_pull_none>,
				<0 RK_PC5 2 &pcfg_pull_none>,
				<0 RK_PB6 2 &pcfg_pull_none>;
		};
		/omit-if-no-ref/
		spi0m0_cs0: spi0m0-cs0 {
			rockchip,pins =
				<0 RK_PC6 2 &pcfg_pull_none>;
		};
		/omit-if-no-ref/
		spi0m0_cs1: spi0m0-cs1 {
			rockchip,pins =
				<0 RK_PC4 2 &pcfg_pull_none>;
		};
		/omit-if-no-ref/
		spi0m1_pins: spi0m1-pins {
			rockchip,pins =
				<2 RK_PD3 3 &pcfg_pull_none>,
				<2 RK_PD0 3 &pcfg_pull_none>,
				<2 RK_PD1 3 &pcfg_pull_none>;
		};
		/omit-if-no-ref/
		spi0m1_cs0: spi0m1-cs0 {
			rockchip,pins =
				<2 RK_PD2 3 &pcfg_pull_none>;
		};
	};
	spi1 {
		/omit-if-no-ref/
		spi1m0_pins: spi1m0-pins {
			rockchip,pins =
				<2 RK_PB5 3 &pcfg_pull_none>,
				<2 RK_PB6 3 &pcfg_pull_none>,
				<2 RK_PB7 4 &pcfg_pull_none>;
		};
		/omit-if-no-ref/
		spi1m0_cs0: spi1m0-cs0 {
			rockchip,pins =
				<2 RK_PC0 4 &pcfg_pull_none>;
		};
		/omit-if-no-ref/
		spi1m0_cs1: spi1m0-cs1 {
			rockchip,pins =
				<2 RK_PC6 3 &pcfg_pull_none>;
		};
		/omit-if-no-ref/
		spi1m1_pins: spi1m1-pins {
			rockchip,pins =
				<3 RK_PC3 3 &pcfg_pull_none>,
				<3 RK_PC2 3 &pcfg_pull_none>,
				<3 RK_PC1 3 &pcfg_pull_none>;
		};
		/omit-if-no-ref/
		spi1m1_cs0: spi1m1-cs0 {
			rockchip,pins =
				<3 RK_PA1 3 &pcfg_pull_none>;
		};
	};
	spi2 {
		/omit-if-no-ref/
		spi2m0_pins: spi2m0-pins {
			rockchip,pins =
				<2 RK_PC1 4 &pcfg_pull_none>,
				<2 RK_PC2 4 &pcfg_pull_none>,
				<2 RK_PC3 4 &pcfg_pull_none>;
		};
		/omit-if-no-ref/
		spi2m0_cs0: spi2m0-cs0 {
			rockchip,pins =
				<2 RK_PC4 4 &pcfg_pull_none>;
		};
		/omit-if-no-ref/
		spi2m0_cs1: spi2m0-cs1 {
			rockchip,pins =
				<2 RK_PC5 4 &pcfg_pull_none>;
		};
		/omit-if-no-ref/
		spi2m1_pins: spi2m1-pins {
			rockchip,pins =
				<3 RK_PA0 3 &pcfg_pull_none>,
				<2 RK_PD7 3 &pcfg_pull_none>,
				<2 RK_PD6 3 &pcfg_pull_none>;
		};
		/omit-if-no-ref/
		spi2m1_cs0: spi2m1-cs0 {
			rockchip,pins =
				<2 RK_PD5 3 &pcfg_pull_none>;
		};
		/omit-if-no-ref/
		spi2m1_cs1: spi2m1-cs1 {
			rockchip,pins =
				<2 RK_PD4 3 &pcfg_pull_none>;
		};
	};
	spi3 {
		/omit-if-no-ref/
		spi3m0_pins: spi3m0-pins {
			rockchip,pins =
				<4 RK_PB3 4 &pcfg_pull_none>,
				<4 RK_PB0 4 &pcfg_pull_none>,
				<4 RK_PB2 4 &pcfg_pull_none>;
		};
		/omit-if-no-ref/
		spi3m0_cs0: spi3m0-cs0 {
			rockchip,pins =
				<4 RK_PA6 4 &pcfg_pull_none>;
		};
		/omit-if-no-ref/
		spi3m0_cs1: spi3m0-cs1 {
			rockchip,pins =
				<4 RK_PA7 4 &pcfg_pull_none>;
		};
		/omit-if-no-ref/
		spi3m1_pins: spi3m1-pins {
			rockchip,pins =
				<4 RK_PC2 2 &pcfg_pull_none>,
				<4 RK_PC5 2 &pcfg_pull_none>,
				<4 RK_PC3 2 &pcfg_pull_none>;
		};
		/omit-if-no-ref/
		spi3m1_cs0: spi3m1-cs0 {
			rockchip,pins =
				<4 RK_PC6 2 &pcfg_pull_none>;
		};
		/omit-if-no-ref/
		spi3m1_cs1: spi3m1-cs1 {
			rockchip,pins =
				<4 RK_PD1 2 &pcfg_pull_none>;
		};
	};
	tsadc {
		/omit-if-no-ref/
		tsadcm0_shut: tsadcm0-shut {
			rockchip,pins =
				<0 RK_PA1 1 &pcfg_pull_none>;
		};
		/omit-if-no-ref/
		tsadcm1_shut: tsadcm1-shut {
			rockchip,pins =
				<0 RK_PA2 2 &pcfg_pull_none>;
		};
		/omit-if-no-ref/
		tsadc_shutorg: tsadc-shutorg {
			rockchip,pins =
				<0 RK_PA1 2 &pcfg_pull_none>;
		};
	};
	uart0 {
		/omit-if-no-ref/
		uart0_xfer: uart0-xfer {
			rockchip,pins =
				<0 RK_PC0 3 &pcfg_pull_up>,
				<0 RK_PC1 3 &pcfg_pull_up>;
		};
		/omit-if-no-ref/
		uart0_ctsn: uart0-ctsn {
			rockchip,pins =
				<0 RK_PC7 3 &pcfg_pull_none>;
		};
		/omit-if-no-ref/
		uart0_rtsn: uart0-rtsn {
			rockchip,pins =
				<0 RK_PC4 3 &pcfg_pull_none>;
		};
	};
	uart1 {
		/omit-if-no-ref/
		uart1m0_xfer: uart1m0-xfer {
			rockchip,pins =
				<2 RK_PB3 2 &pcfg_pull_up>,
				<2 RK_PB4 2 &pcfg_pull_up>;
		};
		/omit-if-no-ref/
		uart1m0_ctsn: uart1m0-ctsn {
			rockchip,pins =
				<2 RK_PB6 2 &pcfg_pull_none>;
		};
		/omit-if-no-ref/
		uart1m0_rtsn: uart1m0-rtsn {
			rockchip,pins =
				<2 RK_PB5 2 &pcfg_pull_none>;
		};
		/omit-if-no-ref/
		uart1m1_xfer: uart1m1-xfer {
			rockchip,pins =
				<3 RK_PD7 4 &pcfg_pull_up>,
				<3 RK_PD6 4 &pcfg_pull_up>;
		};
		/omit-if-no-ref/
		uart1m1_ctsn: uart1m1-ctsn {
			rockchip,pins =
				<4 RK_PC1 4 &pcfg_pull_none>;
		};
		/omit-if-no-ref/
		uart1m1_rtsn: uart1m1-rtsn {
			rockchip,pins =
				<4 RK_PB6 4 &pcfg_pull_none>;
		};
	};
	uart2 {
		/omit-if-no-ref/
		uart2m0_xfer: uart2m0-xfer {
			rockchip,pins =
				<0 RK_PD0 1 &pcfg_pull_up>,
				<0 RK_PD1 1 &pcfg_pull_up>;
		};
		/omit-if-no-ref/
		uart2m1_xfer: uart2m1-xfer {
			rockchip,pins =
				<1 RK_PD6 2 &pcfg_pull_up>,
				<1 RK_PD5 2 &pcfg_pull_up>;
		};
	};
	uart3 {
		/omit-if-no-ref/
		uart3m0_xfer: uart3m0-xfer {
			rockchip,pins =
				<1 RK_PA0 2 &pcfg_pull_up>,
				<1 RK_PA1 2 &pcfg_pull_up>;
		};
		/omit-if-no-ref/
		uart3m0_ctsn: uart3m0-ctsn {
			rockchip,pins =
				<1 RK_PA3 2 &pcfg_pull_none>;
		};
		/omit-if-no-ref/
		uart3m0_rtsn: uart3m0-rtsn {
			rockchip,pins =
				<1 RK_PA2 2 &pcfg_pull_none>;
		};
		/omit-if-no-ref/
		uart3m1_xfer: uart3m1-xfer {
			rockchip,pins =
				<3 RK_PC0 4 &pcfg_pull_up>,
				<3 RK_PB7 4 &pcfg_pull_up>;
		};
	};
	uart4 {
		/omit-if-no-ref/
		uart4m0_xfer: uart4m0-xfer {
			rockchip,pins =
				<1 RK_PA4 2 &pcfg_pull_up>,
				<1 RK_PA6 2 &pcfg_pull_up>;
		};
		/omit-if-no-ref/
		uart4m0_ctsn: uart4m0-ctsn {
			rockchip,pins =
				<1 RK_PA7 2 &pcfg_pull_none>;
		};
		/omit-if-no-ref/
		uart4m0_rtsn: uart4m0-rtsn {
			rockchip,pins =
				<1 RK_PA5 2 &pcfg_pull_none>;
		};
		/omit-if-no-ref/
		uart4m1_xfer: uart4m1-xfer {
			rockchip,pins =
				<3 RK_PB1 4 &pcfg_pull_up>,
				<3 RK_PB2 4 &pcfg_pull_up>;
		};
	};
	uart5 {
		/omit-if-no-ref/
		uart5m0_xfer: uart5m0-xfer {
			rockchip,pins =
				<2 RK_PA1 3 &pcfg_pull_up>,
				<2 RK_PA2 3 &pcfg_pull_up>;
		};
		/omit-if-no-ref/
		uart5m0_ctsn: uart5m0-ctsn {
			rockchip,pins =
				<1 RK_PD7 3 &pcfg_pull_none>;
		};
		/omit-if-no-ref/
		uart5m0_rtsn: uart5m0-rtsn {
			rockchip,pins =
				<2 RK_PA0 3 &pcfg_pull_none>;
		};
		/omit-if-no-ref/
		uart5m1_xfer: uart5m1-xfer {
			rockchip,pins =
				<3 RK_PC3 4 &pcfg_pull_up>,
				<3 RK_PC2 4 &pcfg_pull_up>;
		};
	};
	uart6 {
		/omit-if-no-ref/
		uart6m0_xfer: uart6m0-xfer {
			rockchip,pins =
				<2 RK_PA3 3 &pcfg_pull_up>,
				<2 RK_PA4 3 &pcfg_pull_up>;
		};
		/omit-if-no-ref/
		uart6m0_ctsn: uart6m0-ctsn {
			rockchip,pins =
				<2 RK_PC0 3 &pcfg_pull_none>;
		};
		/omit-if-no-ref/
		uart6m0_rtsn: uart6m0-rtsn {
			rockchip,pins =
				<2 RK_PB7 3 &pcfg_pull_none>;
		};
		/omit-if-no-ref/
		uart6m1_xfer: uart6m1-xfer {
			rockchip,pins =
				<1 RK_PD6 3 &pcfg_pull_up>,
				<1 RK_PD5 3 &pcfg_pull_up>;
		};
	};
	uart7 {
		/omit-if-no-ref/
		uart7m0_xfer: uart7m0-xfer {
			rockchip,pins =
				<2 RK_PA5 3 &pcfg_pull_up>,
				<2 RK_PA6 3 &pcfg_pull_up>;
		};
		/omit-if-no-ref/
		uart7m0_ctsn: uart7m0-ctsn {
			rockchip,pins =
				<2 RK_PC2 3 &pcfg_pull_none>;
		};
		/omit-if-no-ref/
		uart7m0_rtsn: uart7m0-rtsn {
			rockchip,pins =
				<2 RK_PC1 3 &pcfg_pull_none>;
		};
		/omit-if-no-ref/
		uart7m1_xfer: uart7m1-xfer {
			rockchip,pins =
				<3 RK_PC5 4 &pcfg_pull_up>,
				<3 RK_PC4 4 &pcfg_pull_up>;
		};
		/omit-if-no-ref/
		uart7m2_xfer: uart7m2-xfer {
			rockchip,pins =
				<4 RK_PA3 4 &pcfg_pull_up>,
				<4 RK_PA2 4 &pcfg_pull_up>;
		};
	};
	uart8 {
		/omit-if-no-ref/
		uart8m0_xfer: uart8m0-xfer {
			rockchip,pins =
				<2 RK_PC6 2 &pcfg_pull_up>,
				<2 RK_PC5 3 &pcfg_pull_up>;
		};
		/omit-if-no-ref/
		uart8m0_ctsn: uart8m0-ctsn {
			rockchip,pins =
				<2 RK_PB2 3 &pcfg_pull_none>;
		};
		/omit-if-no-ref/
		uart8m0_rtsn: uart8m0-rtsn {
			rockchip,pins =
				<2 RK_PB1 3 &pcfg_pull_none>;
		};
		/omit-if-no-ref/
		uart8m1_xfer: uart8m1-xfer {
			rockchip,pins =
				<3 RK_PA0 4 &pcfg_pull_up>,
				<2 RK_PD7 4 &pcfg_pull_up>;
		};
	};
	uart9 {
		/omit-if-no-ref/
		uart9m0_xfer: uart9m0-xfer {
			rockchip,pins =
				<2 RK_PA7 3 &pcfg_pull_up>,
				<2 RK_PB0 3 &pcfg_pull_up>;
		};
		/omit-if-no-ref/
		uart9m0_ctsn: uart9m0-ctsn {
			rockchip,pins =
				<2 RK_PC4 3 &pcfg_pull_none>;
		};
		/omit-if-no-ref/
		uart9m0_rtsn: uart9m0-rtsn {
			rockchip,pins =
				<2 RK_PC3 3 &pcfg_pull_none>;
		};
		/omit-if-no-ref/
		uart9m1_xfer: uart9m1-xfer {
			rockchip,pins =
				<4 RK_PC6 4 &pcfg_pull_up>,
				<4 RK_PC5 4 &pcfg_pull_up>;
		};
		/omit-if-no-ref/
		uart9m2_xfer: uart9m2-xfer {
			rockchip,pins =
				<4 RK_PA5 4 &pcfg_pull_up>,
				<4 RK_PA4 4 &pcfg_pull_up>;
		};
	};
	vop {
		/omit-if-no-ref/
		vopm0_pins: vopm0-pins {
			rockchip,pins =
				<0 RK_PC3 2 &pcfg_pull_none>;
		};
		/omit-if-no-ref/
		vopm1_pins: vopm1-pins {
			rockchip,pins =
				<3 RK_PC4 2 &pcfg_pull_none>;
		};
	};
};
&pinctrl {
	spi0-hs {
		/omit-if-no-ref/
		spi0m0_pins_hs: spi0m0-pins {
			rockchip,pins =
				<0 RK_PB5 2 &pcfg_pull_up_drv_level_1>,
				<0 RK_PC5 2 &pcfg_pull_up_drv_level_1>,
				<0 RK_PB6 2 &pcfg_pull_up_drv_level_1>;
		};
		/omit-if-no-ref/
		spi0m0_cs0_hs: spi0m0-cs0 {
			rockchip,pins =
				<0 RK_PC6 2 &pcfg_pull_up_drv_level_1>;
		};
		/omit-if-no-ref/
		spi0m0_cs1_hs: spi0m0-cs1 {
			rockchip,pins =
				<0 RK_PC4 2 &pcfg_pull_up_drv_level_1>;
		};
		/omit-if-no-ref/
		spi0m1_pins_hs: spi0m1-pins {
			rockchip,pins =
				<2 RK_PD3 3 &pcfg_pull_up_drv_level_1>,
				<2 RK_PD0 3 &pcfg_pull_up_drv_level_1>,
				<2 RK_PD1 3 &pcfg_pull_up_drv_level_1>;
		};
		/omit-if-no-ref/
		spi0m1_cs0_hs: spi0m1-cs0 {
			rockchip,pins =
				<2 RK_PD2 3 &pcfg_pull_up_drv_level_1>;
		};
	};
	spi1-hs {
		/omit-if-no-ref/
		spi1m0_pins_hs: spi1m0-pins {
			rockchip,pins =
				<2 RK_PB5 3 &pcfg_pull_up_drv_level_1>,
				<2 RK_PB6 3 &pcfg_pull_up_drv_level_1>,
				<2 RK_PB7 4 &pcfg_pull_up_drv_level_1>;
		};
		/omit-if-no-ref/
		spi1m0_cs0_hs: spi1m0-cs0 {
			rockchip,pins =
				<2 RK_PC0 4 &pcfg_pull_up_drv_level_1>;
		};
		/omit-if-no-ref/
		spi1m0_cs1_hs: spi1m0-cs1 {
			rockchip,pins =
				<2 RK_PC6 3 &pcfg_pull_up_drv_level_1>;
		};
		/omit-if-no-ref/
		spi1m1_pins_hs: spi1m1-pins {
			rockchip,pins =
				<3 RK_PC3 3 &pcfg_pull_up_drv_level_1>,
				<3 RK_PC2 3 &pcfg_pull_up_drv_level_1>,
				<3 RK_PC1 3 &pcfg_pull_up_drv_level_1>;
		};
		/omit-if-no-ref/
		spi1m1_cs0_hs: spi1m1-cs0 {
			rockchip,pins =
				<3 RK_PA1 3 &pcfg_pull_up_drv_level_1>;
		};
	};
	spi2-hs {
		/omit-if-no-ref/
		spi2m0_pins_hs: spi2m0-pins {
			rockchip,pins =
				<2 RK_PC1 4 &pcfg_pull_up_drv_level_1>,
				<2 RK_PC2 4 &pcfg_pull_up_drv_level_1>,
				<2 RK_PC3 4 &pcfg_pull_up_drv_level_1>;
		};
		/omit-if-no-ref/
		spi2m0_cs0_hs: spi2m0-cs0 {
			rockchip,pins =
				<2 RK_PC4 4 &pcfg_pull_up_drv_level_1>;
		};
		/omit-if-no-ref/
		spi2m0_cs1_hs: spi2m0-cs1 {
			rockchip,pins =
				<2 RK_PC5 4 &pcfg_pull_up_drv_level_1>;
		};
		/omit-if-no-ref/
		spi2m1_pins_hs: spi2m1-pins {
			rockchip,pins =
				<3 RK_PA0 3 &pcfg_pull_up_drv_level_1>,
				<2 RK_PD7 3 &pcfg_pull_up_drv_level_1>,
				<2 RK_PD6 3 &pcfg_pull_up_drv_level_1>;
		};
		/omit-if-no-ref/
		spi2m1_cs0_hs: spi2m1-cs0 {
			rockchip,pins =
				<2 RK_PD5 3 &pcfg_pull_up_drv_level_1>;
		};
		/omit-if-no-ref/
		spi2m1_cs1_hs: spi2m1-cs1 {
			rockchip,pins =
				<2 RK_PD4 3 &pcfg_pull_up_drv_level_1>;
		};
	};
	spi3-hs {
		/omit-if-no-ref/
		spi3m0_pins_hs: spi3m0-pins {
			rockchip,pins =
				<4 RK_PB3 4 &pcfg_pull_up_drv_level_1>,
				<4 RK_PB0 4 &pcfg_pull_up_drv_level_1>,
				<4 RK_PB2 4 &pcfg_pull_up_drv_level_1>;
		};
		/omit-if-no-ref/
		spi3m0_cs0_hs: spi3m0-cs0 {
			rockchip,pins =
				<4 RK_PA6 4 &pcfg_pull_up_drv_level_1>;
		};
		/omit-if-no-ref/
		spi3m0_cs1_hs: spi3m0-cs1 {
			rockchip,pins =
				<4 RK_PA7 4 &pcfg_pull_up_drv_level_1>;
		};
		/omit-if-no-ref/
		spi3m1_pins_hs: spi3m1-pins {
			rockchip,pins =
				<4 RK_PC2 2 &pcfg_pull_up_drv_level_1>,
				<4 RK_PC5 2 &pcfg_pull_up_drv_level_1>,
				<4 RK_PC3 2 &pcfg_pull_up_drv_level_1>;
		};
		/omit-if-no-ref/
		spi3m1_cs0_hs: spi3m1-cs0 {
			rockchip,pins =
				<4 RK_PC6 2 &pcfg_pull_up_drv_level_1>;
		};
		/omit-if-no-ref/
		spi3m1_cs1_hs: spi3m1-cs1 {
			rockchip,pins =
				<4 RK_PD1 2 &pcfg_pull_up_drv_level_1>;
		};
	};
	gmac-txd-level3 {
		/omit-if-no-ref/
		gmac0_tx_bus2_level3: gmac0-tx-bus2-level3 {
			rockchip,pins =
				<2 RK_PB3 1 &pcfg_pull_none_drv_level_3>,
				<2 RK_PB4 1 &pcfg_pull_none_drv_level_3>,
				<2 RK_PB5 1 &pcfg_pull_none>;
		};
		/omit-if-no-ref/
		gmac0_rgmii_bus_level3: gmac0-rgmii-bus-level3 {
			rockchip,pins =
				<2 RK_PA3 2 &pcfg_pull_none>,
				<2 RK_PA4 2 &pcfg_pull_none>,
				<2 RK_PA6 2 &pcfg_pull_none_drv_level_3>,
				<2 RK_PA7 2 &pcfg_pull_none_drv_level_3>;
		};
		/omit-if-no-ref/
		gmac1m0_tx_bus2_level3: gmac1m0-tx-bus2-level3 {
			rockchip,pins =
				<3 RK_PB5 3 &pcfg_pull_none_drv_level_3>,
				<3 RK_PB6 3 &pcfg_pull_none_drv_level_3>,
				<3 RK_PB7 3 &pcfg_pull_none>;
		};
		/omit-if-no-ref/
		gmac1m0_rgmii_bus_level3: gmac1m0-rgmii-bus-level3 {
			rockchip,pins =
				<3 RK_PA4 3 &pcfg_pull_none>,
				<3 RK_PA5 3 &pcfg_pull_none>,
				<3 RK_PA2 3 &pcfg_pull_none_drv_level_3>,
				<3 RK_PA3 3 &pcfg_pull_none_drv_level_3>;
		};
		/omit-if-no-ref/
		gmac1m1_tx_bus2_level3: gmac1m1-tx-bus2-level3 {
			rockchip,pins =
				<4 RK_PA4 3 &pcfg_pull_none_drv_level_3>,
				<4 RK_PA5 3 &pcfg_pull_none_drv_level_3>,
				<4 RK_PA6 3 &pcfg_pull_none>;
		};
		/omit-if-no-ref/
		gmac1m1_rgmii_bus_level3: gmac1m1-rgmii-bus-level3 {
			rockchip,pins =
				<4 RK_PA1 3 &pcfg_pull_none>,
				<4 RK_PA2 3 &pcfg_pull_none>,
				<3 RK_PD6 3 &pcfg_pull_none_drv_level_3>,
				<3 RK_PD7 3 &pcfg_pull_none_drv_level_3>;
		};
	};
	gmac-txc-level2 {
		/omit-if-no-ref/
		gmac0_rgmii_clk_level2: gmac0-rgmii-clk-level2 {
			rockchip,pins =
				<2 RK_PA5 2 &pcfg_pull_none>,
				<2 RK_PB0 2 &pcfg_pull_none_drv_level_2>;
		};
		/omit-if-no-ref/
		gmac1m0_rgmii_clk_level2: gmac1m0-rgmii-clk-level2 {
			rockchip,pins =
				<3 RK_PA7 3 &pcfg_pull_none>,
				<3 RK_PA6 3 &pcfg_pull_none_drv_level_2>;
		};
		/omit-if-no-ref/
		gmac1m1_rgmii_clk_level2: gmac1m1-rgmii-clk-level2 {
			rockchip,pins =
				<4 RK_PA3 3 &pcfg_pull_none>,
				<4 RK_PA0 3 &pcfg_pull_none_drv_level_2>;
		};
	};
	tsadc {
		/omit-if-no-ref/
		tsadc_pin: tsadc-pin {
			rockchip,pins =
				<0 RK_PA1 0 &pcfg_pull_none>;
		};
	};
	lcdc {
		/omit-if-no-ref/
		lcdc_clock: lcdc-clock {
			rockchip,pins =
				<3 RK_PA0 1 &pcfg_pull_none>,
				<3 RK_PC3 1 &pcfg_pull_none>,
				<3 RK_PC1 1 &pcfg_pull_none>,
				<3 RK_PC2 1 &pcfg_pull_none>;
		};
		/omit-if-no-ref/
		lcdc_data16: lcdc-data16 {
			rockchip,pins =
				<2 RK_PD3 1 &pcfg_pull_none>,
				<2 RK_PD4 1 &pcfg_pull_none>,
				<2 RK_PD5 1 &pcfg_pull_none>,
				<2 RK_PD6 1 &pcfg_pull_none>,
				<2 RK_PD7 1 &pcfg_pull_none>,
				<3 RK_PA3 1 &pcfg_pull_none>,
				<3 RK_PA4 1 &pcfg_pull_none>,
				<3 RK_PA5 1 &pcfg_pull_none>,
				<3 RK_PA6 1 &pcfg_pull_none>,
				<3 RK_PA7 1 &pcfg_pull_none>,
				<3 RK_PB0 1 &pcfg_pull_none>,
				<3 RK_PB4 1 &pcfg_pull_none>,
				<3 RK_PB5 1 &pcfg_pull_none>,
				<3 RK_PB6 1 &pcfg_pull_none>,
				<3 RK_PB7 1 &pcfg_pull_none>,
				<3 RK_PC0 1 &pcfg_pull_none>;
		};
		/omit-if-no-ref/
		lcdc_data18: lcdc-data18 {
			rockchip,pins =
				<2 RK_PD2 1 &pcfg_pull_none>,
				<2 RK_PD3 1 &pcfg_pull_none>,
				<2 RK_PD4 1 &pcfg_pull_none>,
				<2 RK_PD5 1 &pcfg_pull_none>,
				<2 RK_PD6 1 &pcfg_pull_none>,
				<2 RK_PD7 1 &pcfg_pull_none>,
				<3 RK_PA3 1 &pcfg_pull_none>,
				<3 RK_PA4 1 &pcfg_pull_none>,
				<3 RK_PA5 1 &pcfg_pull_none>,
				<3 RK_PA6 1 &pcfg_pull_none>,
				<3 RK_PA7 1 &pcfg_pull_none>,
				<3 RK_PB0 1 &pcfg_pull_none>,
				<3 RK_PB3 1 &pcfg_pull_none>,
				<3 RK_PB4 1 &pcfg_pull_none>,
				<3 RK_PB5 1 &pcfg_pull_none>,
				<3 RK_PB6 1 &pcfg_pull_none>,
				<3 RK_PB7 1 &pcfg_pull_none>,
				<3 RK_PC0 1 &pcfg_pull_none>;
		};
	};
};
